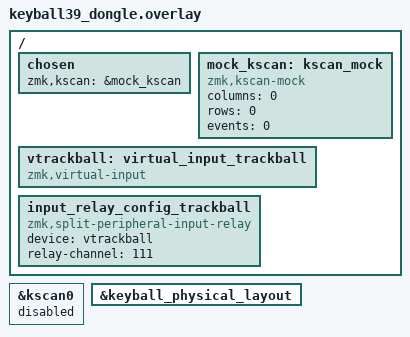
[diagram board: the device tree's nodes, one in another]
#include "keyball39.dtsi"

&kscan0 {
    status = "disabled";
};

&keyball_physical_layout {
    /delete-property/ kscan;
};

/ {
    chosen {
        zmk,kscan = &mock_kscan;
    };

    mock_kscan: kscan_mock {
        compatible = "zmk,kscan-mock";
        columns = <0>;
        rows = <0>;
        events = <0>;
    };

    vtrackball: virtual_input_trackball {
        compatible = "zmk,virtual-input";
    };

    input_relay_config_trackball {
        compatible = "zmk,split-peripheral-input-relay";
        device = <&vtrackball>;
        relay-channel = <111>;
    };
};
